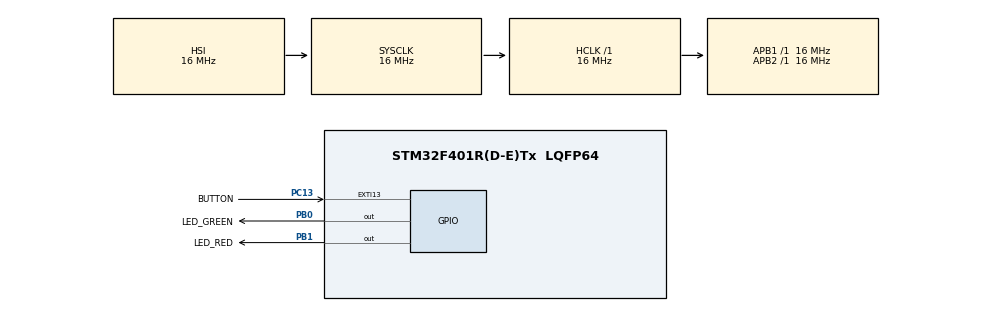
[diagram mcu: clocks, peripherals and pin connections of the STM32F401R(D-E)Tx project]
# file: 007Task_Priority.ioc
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FREERTOS.Tasks01=defaultTask,24,128,StartDefaultTask,Default,NULL,Dynamic,NULL,NULL
Mcu.Family=STM32F4
Mcu.Name=STM32F401R(D-E)Tx
Mcu.Package=LQFP64
NVIC.EXTI15_10_IRQn=true\:6\:0\:true\:false\:true\:false\:true\:true\:true
NVIC.PriorityGroup=NVIC_PRIORITYGROUP_4
NVIC.TIM5_IRQn=true\:15\:0\:false\:false\:true\:false\:false\:true\:true
NVIC.TimeBase=TIM5_IRQn
NVIC.TimeBaseIP=TIM5
PB0.GPIO_Label=LED_GREEN
PB0.Signal=GPIO_Output
PB1.GPIO_Label=LED_RED
PB1.Signal=GPIO_Output
PC13-ANTI_TAMP.GPIO_Label=BUTTON
PC13-ANTI_TAMP.GPIO_ModeDefaultEXTI=GPIO_MODE_IT_FALLING
PC13-ANTI_TAMP.GPIO_PuPd=GPIO_PULLUP
PC13-ANTI_TAMP.Signal=GPXTI13
ProjectManager.HeapSize=0x200
ProjectManager.StackSize=0x400
ProjectManager.TargetToolchain=STM32CubeIDE
RCC.AHBFreq_Value=16000000
RCC.APB1Freq_Value=16000000
RCC.APB2Freq_Value=16000000
RCC.CortexFreq_Value=16000000
RCC.HSE_VALUE=25000000
RCC.HSI_VALUE=16000000
RCC.LSE_VALUE=32768
RCC.SYSCLKFreq_VALUE=16000000
RCC.VCOOutputFreq_Value=192000000
VP_FREERTOS_VS_CMSIS_V2.Mode=CMSIS_V2
VP_SYS_VS_tim5.Mode=TIM5
board=custom

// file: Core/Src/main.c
/* USER CODE BEGIN Header */
/**
  ******************************************************************************
  * @file           : main.c
  * @brief          : Main program body
  ******************************************************************************
  * @attention
  *
  * Copyright (c) 2026 STMicroelectronics.
  * All rights reserved.
  *
  * This software is licensed under terms that can be found in the LICENSE file
  * in the root directory of this software component.
  * If no LICENSE file comes with this software, it is provided AS-IS.
  *
  ******************************************************************************
  */
/* USER CODE END Header */
#include "main.h"
#include "cmsis_os.h"

/* USER CODE BEGIN Includes */
#include<stdio.h>
#include "FreeRTOS.h"
#include "task.h"
#include "SEGGER_SYSVIEW.h"
#include <string.h>
/* USER CODE END Includes */

/* Definitions for defaultTask */
osThreadId_t defaultTaskHandle;
const osThreadAttr_t defaultTask_attributes = {
  .name = "defaultTask",
  .stack_size = 128 * 4,
  .priority = (osPriority_t) osPriorityNormal,
};
/* USER CODE BEGIN PV */
#define DEMCR      (*(volatile uint32_t*)0xE000EDFC)
#define DWT_CTRL   (*(volatile uint32_t*)0xE0001000)
#define DWT_CYCCNT (*(volatile uint32_t*)0xE0001004)

volatile BaseType_t status_button = 0;

TaskHandle_t task1_handle = NULL;
TaskHandle_t task2_handle = NULL;

BaseType_t Status;
/* USER CODE END PV */

void SystemClock_Config(void);
static void MX_GPIO_Init(void);
void StartDefaultTask(void *argument);

/* USER CODE BEGIN PFP */
/* USER CODE BEGIN PFP */

static void led_green_handler(void *parameters);
static void led_red_handler(void *parameters);
static void switch_priority(void);

/* USER CODE END PFP */

int main(void)
{

  /* MCU Configuration--------------------------------------------------------*/

  /* Reset of all peripherals, Initializes the Flash interface and the Systick. */
  HAL_Init();

  /* Configure the system clock */
  SystemClock_Config();

  /* Initialize all configured peripherals */
  MX_GPIO_Init();
  /* USER CODE BEGIN 2 */
  DEMCR |= (1 << 24);      // Enable trace
      DWT_CYCCNT = 0;          // Reset cycle counter
      DWT_CTRL |= (1 << 0);    // Enable CYCCNT

      SEGGER_SYSVIEW_Conf();
      SEGGER_SYSVIEW_Start();
    Status = xTaskCreate(led_green_handler,
                         "Led_green_task",
                         200,
                         NULL,
                         2,
                         &task1_handle);

    configASSERT(Status == pdPASS);

    Status = xTaskCreate(led_red_handler,
                         "Led_red_task",
                         200,
                         NULL,
                         2,
                         &task2_handle);

    configASSERT(Status == pdPASS);

    /* Start FreeRTOS scheduler */
      vTaskStartScheduler();

  /* USER CODE END 2 */

  /* Init scheduler */
  //osKernelInitialize();

  /* Create the thread(s) */
  /* creation of defaultTask */
  //defaultTaskHandle = osThreadNew(StartDefaultTask, NULL, &defaultTask_attributes);

  /* Start scheduler */
  //osKernelStart();

  /* We should never get here as control is now taken by the scheduler */

  /* Infinite loop */
  while (1)
  {

  }
}

void SystemClock_Config(void)
{
  RCC_OscInitTypeDef RCC_OscInitStruct = {0};
  RCC_ClkInitTypeDef RCC_ClkInitStruct = {0};

  /** Configure the main internal regulator output voltage
  */
  __HAL_RCC_PWR_CLK_ENABLE();
  __HAL_PWR_VOLTAGESCALING_CONFIG(PWR_REGULATOR_VOLTAGE_SCALE2);

  /** Initializes the RCC Oscillators according to the specified parameters
  * in the RCC_OscInitTypeDef structure.
  */
  RCC_OscInitStruct.OscillatorType = RCC_OSCILLATORTYPE_HSI;
  RCC_OscInitStruct.HSIState = RCC_HSI_ON;
  RCC_OscInitStruct.HSICalibrationValue = RCC_HSICALIBRATION_DEFAULT;
  RCC_OscInitStruct.PLL.PLLState = RCC_PLL_NONE;
  if (HAL_RCC_OscConfig(&RCC_OscInitStruct) != HAL_OK)
  {
    Error_Handler();
  }

  /** Initializes the CPU, AHB and APB buses clocks
  */
  RCC_ClkInitStruct.ClockType = RCC_CLOCKTYPE_HCLK|RCC_CLOCKTYPE_SYSCLK
                              |RCC_CLOCKTYPE_PCLK1|RCC_CLOCKTYPE_PCLK2;
  RCC_ClkInitStruct.SYSCLKSource = RCC_SYSCLKSOURCE_HSI;
  RCC_ClkInitStruct.AHBCLKDivider = RCC_SYSCLK_DIV1;
  RCC_ClkInitStruct.APB1CLKDivider = RCC_HCLK_DIV1;
  RCC_ClkInitStruct.APB2CLKDivider = RCC_HCLK_DIV1;

  if (HAL_RCC_ClockConfig(&RCC_ClkInitStruct, FLASH_LATENCY_0) != HAL_OK)
  {
    Error_Handler();
  }
}

static void MX_GPIO_Init(void)
{
  GPIO_InitTypeDef GPIO_InitStruct = {0};

  /* GPIO Ports Clock Enable */
  __HAL_RCC_GPIOC_CLK_ENABLE();
  __HAL_RCC_GPIOB_CLK_ENABLE();

  /*Configure GPIO pin Output Level */
  HAL_GPIO_WritePin(GPIOB, LED_GREEN_Pin|LED_RED_Pin, GPIO_PIN_RESET);

  /*Configure GPIO pin : BUTTON_Pin */
  GPIO_InitStruct.Pin = BUTTON_Pin;
  GPIO_InitStruct.Mode = GPIO_MODE_IT_FALLING;
  GPIO_InitStruct.Pull = GPIO_PULLUP;
  HAL_GPIO_Init(BUTTON_GPIO_Port, &GPIO_InitStruct);

  /*Configure GPIO pins : LED_GREEN_Pin LED_RED_Pin */
  GPIO_InitStruct.Pin = LED_GREEN_Pin|LED_RED_Pin;
  GPIO_InitStruct.Mode = GPIO_MODE_OUTPUT_PP;
  GPIO_InitStruct.Pull = GPIO_NOPULL;
  GPIO_InitStruct.Speed = GPIO_SPEED_FREQ_LOW;
  HAL_GPIO_Init(GPIOB, &GPIO_InitStruct);

  /* EXTI interrupt init*/
  HAL_NVIC_SetPriority(EXTI15_10_IRQn, 6, 0);
  HAL_NVIC_EnableIRQ(EXTI15_10_IRQn);

}

/* USER CODE BEGIN 4 */
void switch_priority()
{
	UBaseType_t p1,p2;
	xTaskHandle t1,t2,curr;

	BaseType_t switch_priority = 0;
	portENTER_CRITICAL();
		if(status_button){
			status_button = 0;
			switch_priority = 1;
		}
		portEXIT_CRITICAL();
		if(switch_priority){
			t1 = task1_handle;
			t2 = task2_handle;

			p1 = uxTaskPriorityGet(t1);
			p2 = uxTaskPriorityGet(t2);

			curr = xTaskGetCurrentTaskHandle();
			 if(curr == t1){
				 vTaskPrioritySet(t1,p1);
				 vTaskPrioritySet(t2,p2);
			 }else{
				 vTaskPrioritySet(t1,p2);
				 vTaskPrioritySet(t2,p1);
			 }
		}
}
static void led_green_handler(void *parameters)
{
    while(1)
    {
    	SEGGER_SYSVIEW_PrintfTarget("Toggling green LED");
        HAL_GPIO_TogglePin(GPIOB, LED_GREEN_Pin);

        HAL_Delay(1000);
        switch_priority();
    }
}

static void led_red_handler(void *parameters)
{
    while(1)
    {
    	SEGGER_SYSVIEW_PrintfTarget("Toggling Orange  LED");
        HAL_GPIO_TogglePin(GPIOB, LED_RED_Pin);
        HAL_Delay(800);
        switch_priority();
    }
}

void button_interrupt_handler(void)
{
	traceISR_ENTER();
	status_button = 1;
	traceISR_EXIT();
}
/* USER CODE END 4 */

void StartDefaultTask(void *argument)
{
  for(;;)
  {
    osDelay(1);
  }
}

void HAL_TIM_PeriodElapsedCallback(TIM_HandleTypeDef *htim)
{
  if (htim->Instance == TIM5)
  {
    HAL_IncTick();
  }
}

void Error_Handler(void)
{
  __disable_irq();
  while (1)
  {
  }
}
